# STMP3770 register map
Vendor: Freescale Semiconductor (NXP); Series: STMP37xx; File version: 1.0
CPU: other r0p0, little endian, no MPU, no FPU, 2 interrupt priority bits
Registers are 32-bit, read-write, reset 0x0 unless marked. A register's access mark holds for its fields unless they carry their own. Offsets are from the block's base; [hi:lo] are bit positions.

## UARTDBG — STMP3770 UARTDBG 调试串口外设（ARM PrimeCell PL011 兼容），基地址 0x80070000，用于内核调试输出。包含数据收发、接收状态/错误清除、标志、红外低功耗计数、整数/小数波特率分频、线控、控制、FIFO 中断触发水平、中断屏蔽、原始中断状态、屏蔽后中断状态、中断清除及 DMA 控制等寄存器。
Base 0x80070000
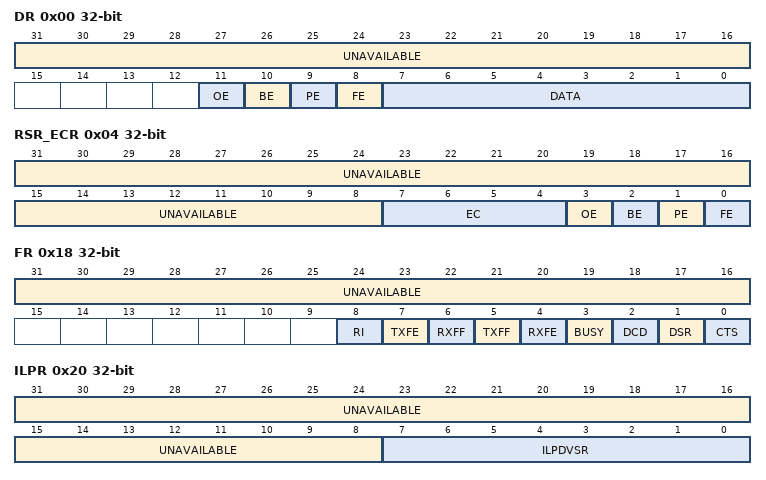
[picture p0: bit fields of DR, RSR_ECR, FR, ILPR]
0x00 DR — UART 数据寄存器，读写收发字节并附带接收错误标志。
  [31:16] UNAVAILABLE — 未实现位，读取值未定义。
  [11] OE — 接收溢出错误标志（Overrun Error），读取时反映 FIFO 溢出状态。
  [10] BE — 接收 Break 错误标志（Break Error），读取时反映最近接收字节是否检测到 Break 条件。
  [9] PE — 接收校验错误标志（Parity Error），读取时反映最近接收字节的校验错误状态。
  [8] FE — 接收帧错误标志（Frame Error），读取时反映最近接收字节的帧错误状态。
  [7:0] DATA — 收发数据字节（8 位），写入时送入发送 FIFO，读取时返回接收 FIFO 数据。
0x04 RSR_ECR — UART 接收状态寄存器（读）/ 错误清除寄存器（写），读取时返回接收错误状态，写入时向 EC 字段写值以清除错误标志。
  [31:8] UNAVAILABLE — 未实现位，读取值未定义。
  [7:4] EC — 错误清除（Error Clear），写入时向该 4 位字段写值以清除接收错误标志。
  [3] OE — 溢出错误状态（Overrun Error）。
  [2] BE — Break 错误状态（Break Error）。
  [1] PE — 校验错误状态（Parity Error）。
  [0] FE — 帧错误状态（Frame Error）。
0x18 FR — UART 标志寄存器（只读），反映 UART 当前状态与 FIFO 状态。
  [31:16] UNAVAILABLE — 未实现位，读取值未定义。
  [8] RI — RI 调制解调器状态输入（Ring Indicator）。
  [7] TXFE — 发送 FIFO 空标志（Transmit FIFO Empty）。
  [6] RXFF — 接收 FIFO 满标志（Receive FIFO Full）。
  [5] TXFF — 发送 FIFO 满标志（Transmit FIFO Full）。
  [4] RXFE — 接收 FIFO 空标志（Receive FIFO Empty）。
  [3] BUSY — 发送忙标志，表示 UART 正在发送数据。
  [2] DCD — DCD 调制解调器状态输入（Data Carrier Detect）。
  [1] DSR — DSR 调制解调器状态输入（Data Set Ready）。
  [0] CTS — CTS 调制解调器状态输入（Clear To Send）。
0x20 ILPR — UART IrDA 低功耗计数寄存器，配置低功耗分频值。
  [31:8] UNAVAILABLE — 未实现位，读取值未定义。
  [7:0] ILPDVSR — IrDA 低功耗分频值（IrDA Low-Power Divisor），用于 IrDA SIR 低功耗模式的波特率生成。
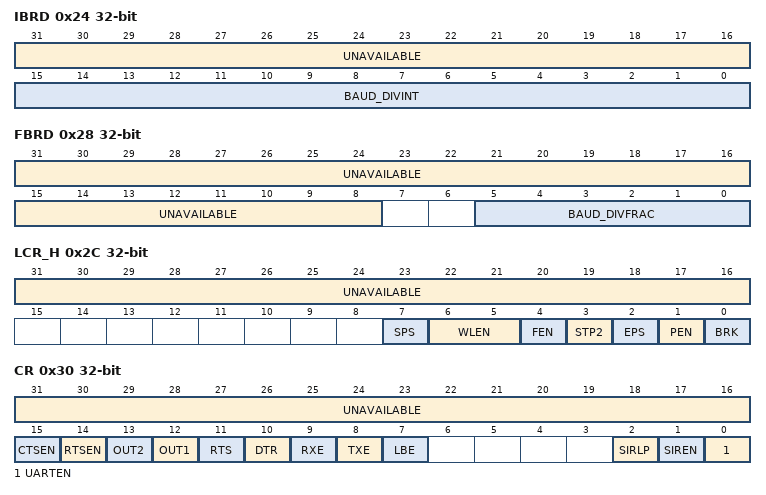
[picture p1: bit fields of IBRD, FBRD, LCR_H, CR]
0x24 IBRD — UART 整数波特率分频寄存器，设置波特率整数分频值。
  [31:16] UNAVAILABLE — 未实现位，读取值未定义。
  [15:0] BAUD_DIVINT — 波特率整数分频值（Baud Rate Integer Divisor），与 FBRD 共同决定 UART 波特率。
0x28 FBRD — UART 小数波特率分频寄存器，设置波特率小数分频值。
  [31:8] UNAVAILABLE — 未实现位，读取值未定义。
  [5:0] BAUD_DIVFRAC — 波特率小数分频值（Baud Rate Fractional Divisor），与 IBRD 共同决定 UART 波特率。
0x2C LCR_H — UART 线控寄存器（高字节），配置数据格式、校验、停止位及 FIFO 使能。
  [31:16] UNAVAILABLE — 未实现位，读取值未定义。
  [7] SPS — Stick 校验选择（Stick Parity Select），置位时强制校验位为固定值。
  [6:5] WLEN — 字长选择（Word Length），00=5 位、01=6 位、10=7 位、11=8 位。
  [4] FEN — FIFO 使能（FIFO Enable），置位时启用发送/接收 FIFO。
  [3] STP2 — 双停止位使能（Two Stop Bits），置位时发送两个停止位。
  [2] EPS — 偶校验选择（Even Parity Select），置位时选择偶校验，清零时选择奇校验。
  [1] PEN — 校验使能（Parity Enable），置位时启用奇偶校验。
  [0] BRK — 发送 Break 控制，置位时强制 UART 输出低电平 Break 条件。
0x30 CR — UART 控制寄存器，使能 UART、收发方向、环回及调制解调器控制。
  [31:16] UNAVAILABLE — 未实现位，读取值未定义。
  [15] CTSEN — CTS 硬件流控使能（CTS Hardware Flow Control Enable），置位时启用 CTS 自动流控。
  [14] RTSEN — RTS 硬件流控使能（RTS Hardware Flow Control Enable），置位时启用 RTS 自动流控。
  [13] OUT2 — OUT2 调制解调器输出控制信号 2。
  [12] OUT1 — OUT1 调制解调器输出控制信号 1。
  [11] RTS — RTS 调制解调器输出控制（Request To Send）。
  [10] DTR — DTR 调制解调器输出控制（Data Terminal Ready）。
  [9] RXE — 接收使能（Receive Enable），置位时允许 UART 接收数据。
  [8] TXE — 发送使能（Transmit Enable），置位时允许 UART 发送数据。
  [7] LBE — 环回使能（Loopback Enable），置位时内部将发送输出连接到接收输入用于自测。
  [2] SIRLP — IrDA SIR 低功耗模式使能（SIR Low-Power），置位时启用 IrDA 低功耗模式。
  [1] SIREN — IrDA SIR 模式使能（SIR Enable），置位时启用 IrDA SIR 编码/解码。
  [0] UARTEN — UART 使能（UART Enable），置位时启动 UART 模块。
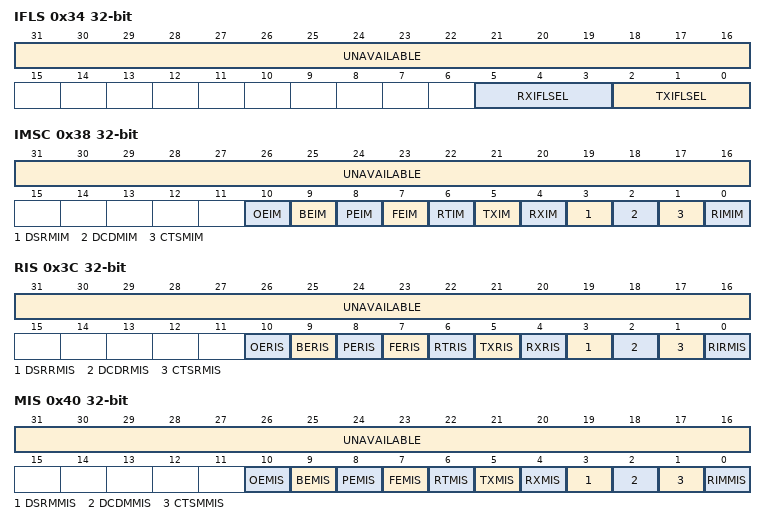
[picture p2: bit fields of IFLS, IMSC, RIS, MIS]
0x34 IFLS — UART FIFO 中断触发水平选择寄存器，设置收发 FIFO 中断阈值。
  [31:16] UNAVAILABLE — 未实现位，读取值未定义。
  [5:3] RXIFLSEL — 接收 FIFO 中断触发水平选择（Receive Interrupt FIFO Level Select），0=非空、1=1/4、2=1/2、3=3/4、4=7/8、5-7=保留无效值。
    0=NOT_EMPTY; 1=ONE_QUARTER; 2=ONE_HALF; 3=THREE_QUARTERS; 4=SEVEN_EIGHTHS; 5=INVALID5; 6=INVALID6; 7=INVALID7
  [2:0] TXIFLSEL — 发送 FIFO 中断触发水平选择（Transmit Interrupt FIFO Level Select），0=空、1=1/4、2=1/2、3=3/4、4=7/8、5-7=保留无效值。
    0=EMPTY; 1=ONE_QUARTER; 2=ONE_HALF; 3=THREE_QUARTERS; 4=SEVEN_EIGHTHS; 5=INVALID5; 6=INVALID6; 7=INVALID7
0x38 IMSC — UART 中断屏蔽设置/清除寄存器，写 1 置位屏蔽对应中断，写 0 清除屏蔽。
  [31:16] UNAVAILABLE — 未实现位，读取值未定义。
  [10] OEIM — 溢出错误中断屏蔽（Overrun Error Interrupt Mask）。
  [9] BEIM — Break 错误中断屏蔽（Break Error Interrupt Mask）。
  [8] PEIM — 校验错误中断屏蔽（Parity Error Interrupt Mask）。
  [7] FEIM — 帧错误中断屏蔽（Framing Error Interrupt Mask）。
  [6] RTIM — 接收超时中断屏蔽（Receive Timeout Interrupt Mask）。
  [5] TXIM — 发送中断屏蔽（Transmit Interrupt Mask）。
  [4] RXIM — 接收中断屏蔽（Receive Interrupt Mask）。
  [3] DSRMIM — DSR 调制解调器中断屏蔽（DSR Interrupt Mask）。
  [2] DCDMIM — DCD 调制解调器中断屏蔽（DCD Interrupt Mask）。
  [1] CTSMIM — CTS 调制解调器中断屏蔽（CTS Interrupt Mask）。
  [0] RIMIM — RI 调制解调器中断屏蔽（Ring Indicator Interrupt Mask）。
0x3C RIS — UART 原始中断状态寄存器（只读），反映各中断源在屏蔽前的原始状态。
  [31:16] UNAVAILABLE — 未实现位，读取值未定义。
  [10] OERIS — 溢出错误原始中断状态（Overrun Error Raw Interrupt Status）。
  [9] BERIS — Break 错误原始中断状态（Break Error Raw Interrupt Status）。
  [8] PERIS — 校验错误原始中断状态（Parity Error Raw Interrupt Status）。
  [7] FERIS — 帧错误原始中断状态（Framing Error Raw Interrupt Status）。
  [6] RTRIS — 接收超时原始中断状态（Receive Timeout Raw Interrupt Status）。
  [5] TXRIS — 发送原始中断状态（Transmit Raw Interrupt Status）。
  [4] RXRIS — 接收原始中断状态（Receive Raw Interrupt Status）。
  [3] DSRRMIS — DSR 原始中断状态（DSR Raw Interrupt Status）。
  [2] DCDRMIS — DCD 原始中断状态（DCD Raw Interrupt Status）。
  [1] CTSRMIS — CTS 原始中断状态（CTS Raw Interrupt Status）。
  [0] RIRMIS — RI 原始中断状态（Ring Indicator Raw Interrupt Status）。
0x40 MIS — UART 屏蔽后中断状态寄存器（只读），反映经过 IMSC 屏蔽后的有效中断状态。
  [31:16] UNAVAILABLE — 未实现位，读取值未定义。
  [10] OEMIS — 溢出错误屏蔽后中断状态（Overrun Error Masked Interrupt Status）。
  [9] BEMIS — Break 错误屏蔽后中断状态（Break Error Masked Interrupt Status）。
  [8] PEMIS — 校验错误屏蔽后中断状态（Parity Error Masked Interrupt Status）。
  [7] FEMIS — 帧错误屏蔽后中断状态（Framing Error Masked Interrupt Status）。
  [6] RTMIS — 接收超时屏蔽后中断状态（Receive Timeout Masked Interrupt Status）。
  [5] TXMIS — 发送屏蔽后中断状态（Transmit Masked Interrupt Status）。
  [4] RXMIS — 接收屏蔽后中断状态（Receive Masked Interrupt Status）。
  [3] DSRMMIS — DSR 屏蔽后中断状态（DSR Masked Interrupt Status）。
  [2] DCDMMIS — DCD 屏蔽后中断状态（DCD Masked Interrupt Status）。
  [1] CTSMMIS — CTS 屏蔽后中断状态（CTS Masked Interrupt Status）。
  [0] RIMMIS — RI 屏蔽后中断状态（Ring Indicator Masked Interrupt Status）。
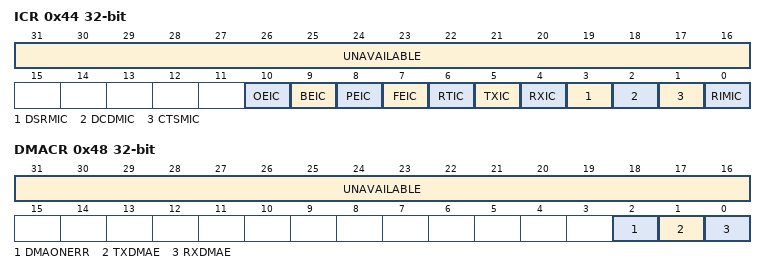
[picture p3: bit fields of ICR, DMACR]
0x44 ICR — UART 中断清除寄存器，写入对应位以清除相应中断状态。
  [31:16] UNAVAILABLE — 未实现位，读取值未定义。
  [10] OEIC — 清除溢出错误中断（Overrun Error Interrupt Clear）。
  [9] BEIC — 清除 Break 错误中断（Break Error Interrupt Clear）。
  [8] PEIC — 清除校验错误中断（Parity Error Interrupt Clear）。
  [7] FEIC — 清除帧错误中断（Framing Error Interrupt Clear）。
  [6] RTIC — 清除接收超时中断（Receive Timeout Interrupt Clear）。
  [5] TXIC — 清除发送中断（Transmit Interrupt Clear）。
  [4] RXIC — 清除接收中断（Receive Interrupt Clear）。
  [3] DSRMIC — 清除 DSR 中断（DSR Interrupt Clear）。
  [2] DCDMIC — 清除 DCD 中断（DCD Interrupt Clear）。
  [1] CTSMIC — 清除 CTS 中断（CTS Interrupt Clear）。
  [0] RIMIC — 清除 RI 中断（Ring Indicator Interrupt Clear）。
0x48 DMACR — UART DMA 控制寄存器，配置 DMA 请求使能及错误处理。
  [31:16] UNAVAILABLE — 未实现位，读取值未定义。
  [2] DMAONERR — 错误时停止 DMA（DMA On Error），置位时接收错误时禁止 DMA 请求。
  [1] TXDMAE — 发送 DMA 使能（Transmit DMA Enable），置位时允许发送 FIFO 触发 DMA 请求。
  [0] RXDMAE — 接收 DMA 使能（Receive DMA Enable），置位时允许接收 FIFO 触发 DMA 请求。
